VERSION ""

NS_ :

BS_:

BU_: ACCM BMS CHM DCDC GWM HVAC IPK SRS TEM

BO_ 80 BMSChargerCmd: 8 BMS
 SG_ HVCurrentCmd : 7|16@0+  (0.1,0) [0|6553.5] "A"  Vector__XXX
 SG_ MaxVoltage   : 23|16@0+ (0.1,0) [0|6553.5] "V"  Vector__XXX

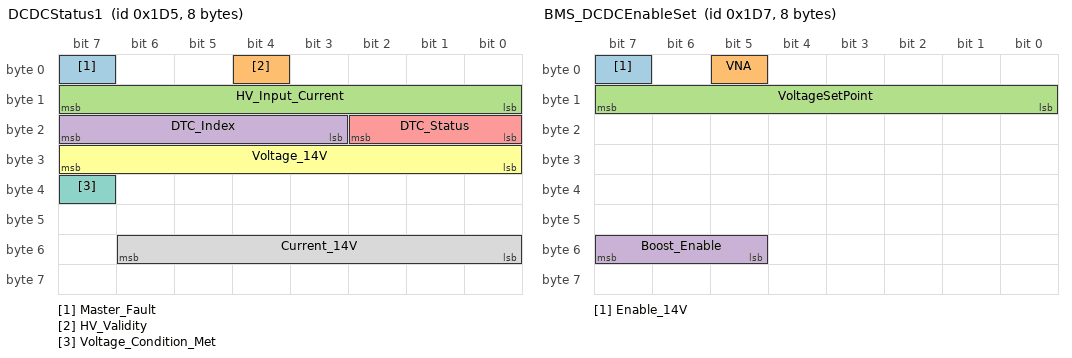
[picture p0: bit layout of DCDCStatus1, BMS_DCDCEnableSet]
BO_ 469 DCDCStatus1: 8 DCDC
 SG_ Master_Fault : 7|1@0+ (1,0) [0|1] "" Vector__XXX
 SG_ HV_Validity : 4|1@0+ (1,0) [0|1] "" Vector__XXX
 SG_ HV_Input_Current : 15|8@0+ (0.1,0) [0|25.5] "A" Vector__XXX
 SG_ DTC_Index : 23|5@0+ (1,0) [0|31] "" Vector__XXX
 SG_ DTC_Status : 18|3@0+ (1,0) [0|7] "" Vector__XXX
 SG_ Voltage_14V : 31|8@0+ (0.078431,0) [0|20] "V" Vector__XXX
 SG_ Voltage_Condition_Met : 39|1@0+ (1,0) [0|1] "" Vector__XXX
 SG_ Current_14V : 54|7@0+ (2,0) [0|254] "A" Vector__XXX

BO_ 471 BMS_DCDCEnableSet: 8 BMS
 SG_ Enable_14V : 7|1@0+ (1,0) [0|1] "" DCDC
 SG_ VNA : 5|1@0+ (1,0) [0|1] "" DCDC
 SG_ VoltageSetPoint : 15|8@0+ (0.022,10.437) [10.437|16.047] "V" DCDC
 SG_ Boost_Enable : 55|3@0+ (1,0) [0|7] "" DCDC

BO_ 624 BMS_FaultStatus: 8 BMS
 SG_ BMSFaultSeverity : 7|4@0+ (1,0) [0|6] "" GWM
 SG_ BMSFaultCode : 3|4@0+ (1,0) [0|15] "" GWM

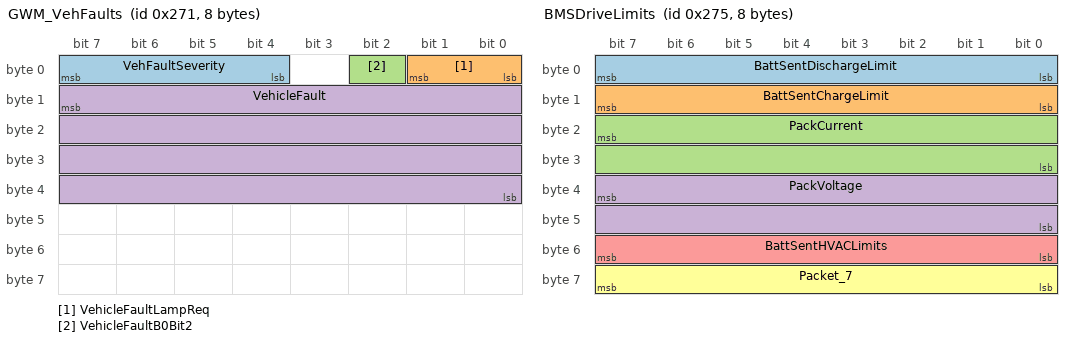
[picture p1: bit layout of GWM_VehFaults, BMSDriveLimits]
BO_ 625 GWM_VehFaults: 8 GWM
 SG_ VehFaultSeverity : 7|4@0+ (1,0) [0|15] "" IPK
 SG_ VehicleFaultLampReq : 1|2@0+ (1,0) [0|3] "" IPK
 SG_ VehicleFaultB0Bit2 : 2|1@0+ (1,0) [0|1] "" Vector__XXX
 SG_ VehicleFault : 15|32@0+ (1,0) [0|4294967295] "" Vector__XXX

BO_ 628 ChrgrSysFaultsTemp: 8 CHM

BO_ 629 BMSDriveLimits: 8 BMS
 SG_ BattSentDischargeLimit : 7|8@0+   (2,0)         [0|510]          "A"  Vector__XXX
 SG_ BattSentChargeLimit    : 15|8@0+  (2,0)         [0|510]          "A"  Vector__XXX
 SG_ PackCurrent            : 23|16@0+ (0.1,-3276.8) [-3276.8|3276.7] "A"  Vector__XXX
 SG_ PackVoltage            : 39|16@0+ (1,0)         [0|65535]        "V"  Vector__XXX
 SG_ BattSentHVACLimits     : 55|8@0+  (2,0)         [0|510]          "A"  Vector__XXX
 SG_ Packet_7               : 63|8@0+  (1,0)         [0|255]          ""   Vector__XXX

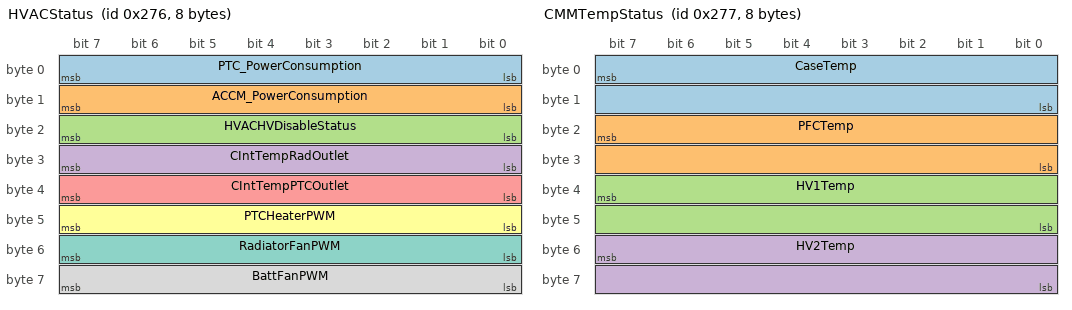
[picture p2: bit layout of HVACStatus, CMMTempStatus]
BO_ 630 HVACStatus: 8 HVAC
 SG_ PTC_PowerConsumption  : 7|8@0+  (0.1,0)      [0|25.5]   "kW"   Vector__XXX
 SG_ ACCM_PowerConsumption : 15|8@0+ (0.1,0)      [0|25.5]   "kW"   Vector__XXX
 SG_ HVACHVDisableStatus   : 23|8@0+ (1,0)        [0|255]    ""     Vector__XXX
 SG_ CIntTempRadOutlet     : 31|8@0+ (1,-40)      [-40|215]  "degC" Vector__XXX
 SG_ CIntTempPTCOutlet     : 39|8@0+ (1,-40)      [-40|215]  "degC" Vector__XXX
 SG_ PTCHeaterPWM          : 47|8@0+ (0.392157,0) [0|100]    "%"    Vector__XXX
 SG_ RadiatorFanPWM        : 55|8@0+ (0.392157,0) [0|100]    "%"    Vector__XXX
 SG_ BattFanPWM            : 63|8@0+ (0.392157,0) [0|100]    "%"    Vector__XXX

BO_ 631 CMMTempStatus: 8 CHM
 SG_ CaseTemp : 7|16@0+ (0.03125,0) [0|2047] "degC" Vector__XXX
 SG_ PFCTemp : 23|16@0+ (0.03125,0) [0|2047] "degC" Vector__XXX
 SG_ HV1Temp : 39|16@0+ (0.03125,0) [0|2047] "degC" Vector__XXX
 SG_ HV2Temp : 55|16@0+ (0.03125,0) [0|2047] "degC" Vector__XXX

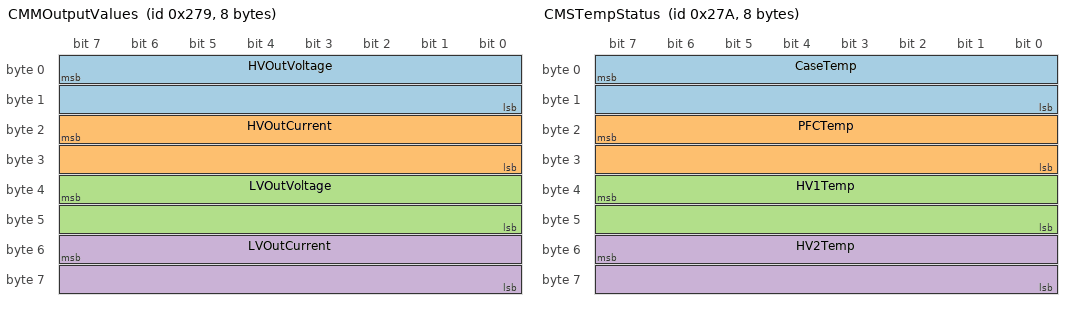
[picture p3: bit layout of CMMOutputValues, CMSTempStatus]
BO_ 633 CMMOutputValues: 8 CHM
 SG_ HVOutVoltage : 7|16@0+ (0.03125,0) [0|2047] "V" Vector__XXX
 SG_ HVOutCurrent : 23|16@0+ (0.03125,0) [0|2047] "A" Vector__XXX
 SG_ LVOutVoltage : 39|16@0+ (0.03125,0) [0|2047] "V" Vector__XXX
 SG_ LVOutCurrent : 55|16@0+ (0.03125,0) [0|2047] "A" Vector__XXX

BO_ 634 CMSTempStatus: 8 CHM
 SG_ CaseTemp : 7|16@0+ (0.03125,0) [0|2047] "degC" Vector__XXX
 SG_ PFCTemp : 23|16@0+ (0.03125,0) [0|2047] "degC" Vector__XXX
 SG_ HV1Temp : 39|16@0+ (0.03125,0) [0|2047] "degC" Vector__XXX
 SG_ HV2Temp : 55|16@0+ (0.03125,0) [0|2047] "degC" Vector__XXX

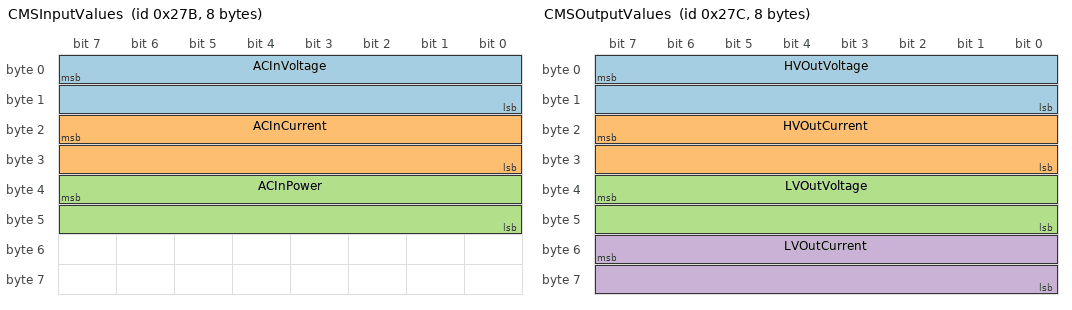
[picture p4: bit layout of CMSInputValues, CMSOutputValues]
BO_ 635 CMSInputValues: 8 CHM
 SG_ ACInVoltage : 7|16@0+ (0.03125,0) [0|2047] "V" Vector__XXX
 SG_ ACInCurrent : 23|16@0+ (0.03125,0) [0|2047] "A" Vector__XXX
 SG_ ACInPower : 39|16@0+ (0.03125,0) [0|2047] "W" Vector__XXX

BO_ 636 CMSOutputValues: 8 CHM
 SG_ HVOutVoltage : 7|16@0+ (0.03125,0) [0|2047] "V" Vector__XXX
 SG_ HVOutCurrent : 23|16@0+ (0.03125,0) [0|2047] "A" Vector__XXX
 SG_ LVOutVoltage : 39|16@0+ (0.03125,0) [0|2047] "V" Vector__XXX
 SG_ LVOutCurrent : 55|16@0+ (0.03125,0) [0|2047] "A" Vector__XXX

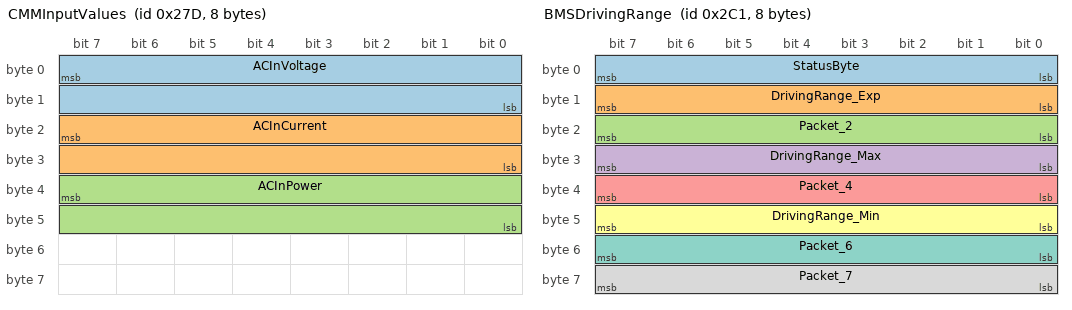
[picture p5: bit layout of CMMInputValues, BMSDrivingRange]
BO_ 637 CMMInputValues: 8 CHM
 SG_ ACInVoltage : 7|16@0+ (0.03125,0) [0|2047] "V" Vector__XXX
 SG_ ACInCurrent : 23|16@0+ (0.03125,0) [0|2047] "A" Vector__XXX
 SG_ ACInPower : 39|16@0+ (0.03125,0) [0|2047] "W" Vector__XXX

BO_ 705 BMSDrivingRange: 8 BMS
 SG_ StatusByte       : 7|8@0+  (1,0)         [0|255]      ""  Vector__XXX
 SG_ DrivingRange_Exp : 15|8@0+ (1.17,-17.85) [-17.85|280] "mi" Vector__XXX
 SG_ Packet_2         : 23|8@0+ (1,0)         [0|255]      ""  Vector__XXX
 SG_ DrivingRange_Max : 31|8@0+ (1.14,-21.0)  [-21|269]    "mi" Vector__XXX
 SG_ Packet_4         : 39|8@0+ (1,0)         [0|255]      ""  Vector__XXX
 SG_ DrivingRange_Min : 47|8@0+ (1.0,-21.58)  [-21.58|234] "mi" Vector__XXX
 SG_ Packet_6         : 55|8@0+ (1,0)         [0|255]      ""  Vector__XXX
 SG_ Packet_7         : 63|8@0+ (1,0)         [0|255]      ""  Vector__XXX

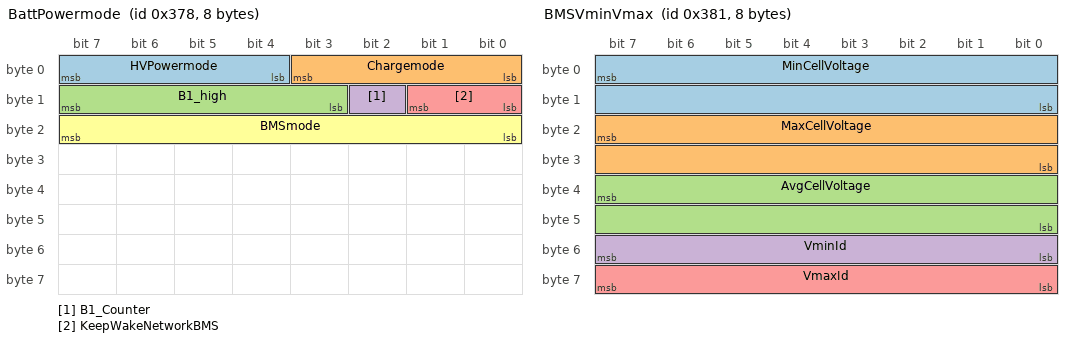
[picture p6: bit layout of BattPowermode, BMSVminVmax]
BO_ 888 BattPowermode: 8 BMS
 SG_ HVPowermode        : 7|4@0+  (1,0) [0|15]  ""  Vector__XXX
 SG_ Chargemode         : 3|4@0+  (1,0) [0|15]  ""  Vector__XXX
 SG_ B1_high            : 15|5@0+ (1,0) [0|31]  ""  Vector__XXX
 SG_ B1_Counter         : 10|1@0+ (1,0) [0|1]   ""  Vector__XXX
 SG_ KeepWakeNetworkBMS : 9|2@0+  (1,0) [0|3]   ""  Vector__XXX
 SG_ BMSmode            : 23|8@0+ (1,0) [0|255] ""  Vector__XXX

BO_ 897 BMSVminVmax: 8 BMS
 SG_ MinCellVoltage : 7|16@0+ (1,0) [2500|3650] "mV" Vector__XXX
 SG_ MaxCellVoltage : 23|16@0+ (1,0) [2500|3650] "mV" Vector__XXX
 SG_ AvgCellVoltage : 39|16@0+ (1,0) [2500|3650] "mV" Vector__XXX
 SG_ VminId : 55|8@0+ (1,0) [0|255] "" Vector__XXX
 SG_ VmaxId : 63|8@0+ (1,0) [0|255] "" Vector__XXX

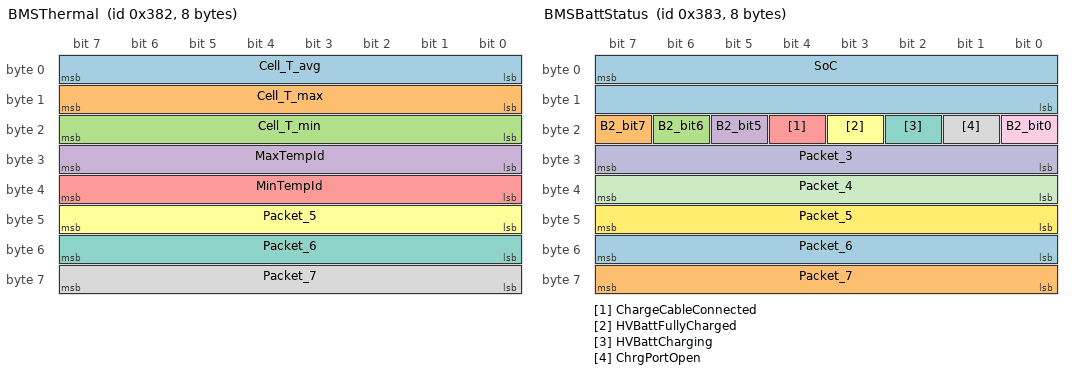
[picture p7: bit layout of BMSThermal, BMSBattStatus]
BO_ 898 BMSThermal: 8 BMS
 SG_ Cell_T_avg : 7|8@0+  (1,-128) [-128|127] "degC" Vector__XXX
 SG_ Cell_T_max : 15|8@0+ (1,-128) [-128|127] "degC" Vector__XXX
 SG_ Cell_T_min : 23|8@0+ (1,-128) [-128|127] "degC" Vector__XXX
 SG_ MaxTempId  : 31|8@0+ (1,0)    [0|255]    ""     Vector__XXX
 SG_ MinTempId  : 39|8@0+ (1,0)    [0|255]    ""     Vector__XXX
 SG_ Packet_5   : 47|8@0+ (1,0)    [0|255]    ""     Vector__XXX
 SG_ Packet_6   : 55|8@0+ (1,0)    [0|255]    ""     Vector__XXX
 SG_ Packet_7   : 63|8@0+ (1,0)    [0|255]    ""     Vector__XXX

BO_ 899 BMSBattStatus: 8 BMS
 SG_ SoC                  : 7|16@0+  (0.1,0) [0|100]  "%"  Vector__XXX
 SG_ B2_bit7              : 23|1@0+  (1,0)   [0|1]     ""   Vector__XXX
 SG_ B2_bit6              : 22|1@0+  (1,0)   [0|1]     ""   Vector__XXX
 SG_ B2_bit5              : 21|1@0+  (1,0)   [0|1]     ""   Vector__XXX
 SG_ ChargeCableConnected : 20|1@0+  (1,0)   [0|1]     ""   Vector__XXX
 SG_ HVBattFullyCharged   : 19|1@0+  (1,0)   [0|1]     ""   Vector__XXX
 SG_ HVBattCharging       : 18|1@0+  (1,0)   [0|1]     ""   Vector__XXX
 SG_ ChrgPortOpen         : 17|1@0+  (1,0)   [0|1]     ""   Vector__XXX
 SG_ B2_bit0              : 16|1@0+  (1,0)   [0|1]     ""   Vector__XXX
 SG_ Packet_3             : 31|8@0+  (1,0)   [0|255]   ""   Vector__XXX
 SG_ Packet_4             : 39|8@0+  (1,0)   [0|255]   ""   Vector__XXX
 SG_ Packet_5             : 47|8@0+  (1,0)   [0|255]   ""   Vector__XXX
 SG_ Packet_6             : 55|8@0+  (1,0)   [0|255]   ""   Vector__XXX
 SG_ Packet_7             : 63|8@0+  (1,0)   [0|255]   ""   Vector__XXX

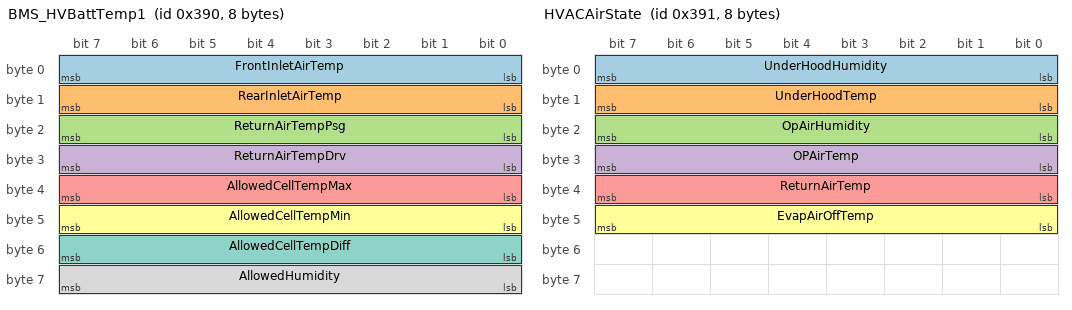
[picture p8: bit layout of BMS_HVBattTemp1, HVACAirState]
BO_ 912 BMS_HVBattTemp1: 8 BMS
 SG_ FrontInletAirTemp   : 7|8@0+  (1,-128) [-128|127] "degC" Vector__XXX
 SG_ RearInletAirTemp    : 15|8@0+ (1,-128) [-128|127] "degC" Vector__XXX
 SG_ ReturnAirTempPsg    : 23|8@0+ (1,-128) [-128|127] "degC" Vector__XXX
 SG_ ReturnAirTempDrv    : 31|8@0+ (1,-128) [-128|127] "degC" Vector__XXX
 SG_ AllowedCellTempMax  : 39|8@0+ (1,-128) [-128|127] "degC" Vector__XXX
 SG_ AllowedCellTempMin  : 47|8@0+ (1,-128) [-128|127] "degC" Vector__XXX
 SG_ AllowedCellTempDiff : 55|8@0+ (1,0)    [0|255]    "degC" Vector__XXX
 SG_ AllowedHumidity     : 63|8@0+ (1,0)    [0|255]    "%"    Vector__XXX

BO_ 913 HVACAirState: 8 HVAC
 SG_ UnderHoodHumidity : 7|8@0+  (2.0,0)  [0|100]    "%"    Vector__XXX
 SG_ UnderHoodTemp     : 15|8@0+ (1,-128) [-128|127]  "degC" Vector__XXX
 SG_ OpAirHumidity     : 23|8@0+ (2.0,0)  [0|100]    "%"    Vector__XXX
 SG_ OPAirTemp         : 31|8@0+ (1,-128) [-128|127]  "degC" Vector__XXX
 SG_ ReturnAirTemp     : 39|8@0+ (1,-128) [-128|127]  "degC" Vector__XXX
 SG_ EvapAirOffTemp    : 47|8@0+ (1,-128) [-128|127]  "degC" Vector__XXX

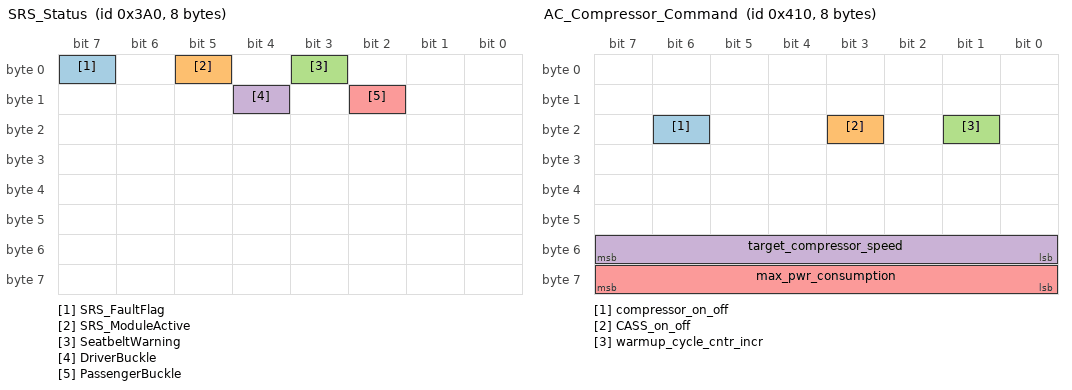
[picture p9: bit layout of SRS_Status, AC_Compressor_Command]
BO_ 928 SRS_Status: 8 SRS
 SG_ SRS_FaultFlag    : 7|1@0+ (1,0) [0|1] "" Vector__XXX
 SG_ SRS_ModuleActive : 5|1@0+ (1,0) [0|1] "" Vector__XXX
 SG_ SeatbeltWarning  : 3|1@0+ (1,0) [0|1] "" Vector__XXX
 SG_ DriverBuckle     : 12|1@0+ (1,0) [0|1] "" Vector__XXX
 SG_ PassengerBuckle  : 10|1@0+ (1,0) [0|1] "" Vector__XXX

BO_ 1040 AC_Compressor_Command: 8 HVAC
 SG_ compressor_on_off       : 22|1@0+ (1,0)   [0|1]     ""    ACCM
 SG_ CASS_on_off             : 19|1@0+ (1,0)   [0|1]     ""    ACCM
 SG_ warmup_cycle_cntr_incr  : 17|1@0+ (1,0)   [0|1]     ""    ACCM
 SG_ target_compressor_speed : 55|8@0+ (60,0)  [0|15180] "rpm" ACCM
 SG_ max_pwr_consumption     : 63|8@0+ (0.1,0) [0|25.3]  "kW"  ACCM

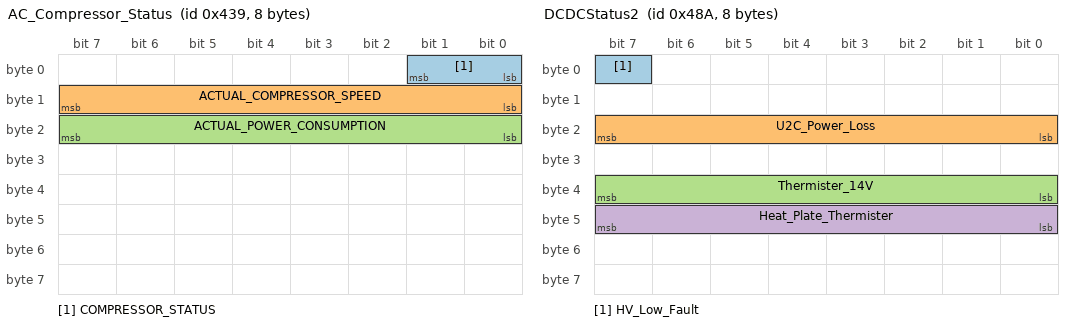
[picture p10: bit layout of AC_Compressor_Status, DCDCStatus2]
BO_ 1081 AC_Compressor_Status: 8 ACCM
 SG_ COMPRESSOR_STATUS : 1|2@0+ (1,0) [0|3] "" Vector__XXX
 SG_ ACTUAL_COMPRESSOR_SPEED : 15|8@0+ (60,0) [0|15180] "rpm" Vector__XXX
 SG_ ACTUAL_POWER_CONSUMPTION : 23|8@0+ (0.1,0) [0|25.3] "kW" Vector__XXX

BO_ 1162 DCDCStatus2: 8 DCDC
 SG_ HV_Low_Fault : 7|1@0+ (1,0) [0|1] "" Vector__XXX
 SG_ U2C_Power_Loss : 23|8@0+ (2,0) [0|510] "W" Vector__XXX
 SG_ Thermister_14V : 39|8@0+ (1,-40) [-40|215] "degC" Vector__XXX
 SG_ Heat_Plate_Thermister : 47|8@0+ (1,-40) [-40|215] "degC" Vector__XXX

BO_ 1169 IPK_Status: 8 IPK
 SG_ IPK_FaultLamps : 2|3@0+ (1,0) [0|7] "" Vector__XXX

BO_ 1170 IPK_Echo: 8 Vector__XXX

BO_ 1557 ChrgrSysLimits: 8 CHM

BO_ 1558 ChrgrSysCtrlEcho: 8 CHM

BO_ 1559 ChrgrSysSts: 8 CHM
 SG_ ChrgrSysBusVoltage : 7|16@0+ (0.1,0) [0|6553.5] "V" Vector__XXX
 SG_ ChrgrSysBusCurrent : 31|8@0+ (0.1,0) [0|25.5]   "A" Vector__XXX

BO_ 1568 BMS_Recvd_0x620: 8 Vector__XXX

BO_ 1786 GWM_VIN: 8 GWM
 SG_ VIN_Frame M  : 7|8@0+  (1,0) [0|2]    "" Vector__XXX
 SG_ VIN_C01  m0  : 15|8@0+ (1,0) [32|127] "" Vector__XXX
 SG_ VIN_C02  m0  : 23|8@0+ (1,0) [32|127] "" Vector__XXX
 SG_ VIN_C03  m0  : 31|8@0+ (1,0) [32|127] "" Vector__XXX
 SG_ VIN_C04  m0  : 39|8@0+ (1,0) [32|127] "" Vector__XXX
 SG_ VIN_C05  m0  : 47|8@0+ (1,0) [32|127] "" Vector__XXX
 SG_ VIN_C06  m0  : 55|8@0+ (1,0) [32|127] "" Vector__XXX
 SG_ VIN_C07  m0  : 63|8@0+ (1,0) [32|127] "" Vector__XXX
 SG_ VIN_C08  m1  : 15|8@0+ (1,0) [32|127] "" Vector__XXX
 SG_ VIN_C09  m1  : 23|8@0+ (1,0) [32|127] "" Vector__XXX
 SG_ VIN_C10  m1  : 31|8@0+ (1,0) [32|127] "" Vector__XXX
 SG_ VIN_C11  m1  : 39|8@0+ (1,0) [32|127] "" Vector__XXX
 SG_ VIN_C12  m1  : 47|8@0+ (1,0) [32|127] "" Vector__XXX
 SG_ VIN_C13  m1  : 55|8@0+ (1,0) [32|127] "" Vector__XXX
 SG_ VIN_C14  m1  : 63|8@0+ (1,0) [32|127] "" Vector__XXX
 SG_ VIN_C15  m2  : 15|8@0+ (1,0) [32|127] "" Vector__XXX
 SG_ VIN_C16  m2  : 23|8@0+ (1,0) [32|127] "" Vector__XXX
 SG_ VIN_C17  m2  : 31|8@0+ (1,0) [32|127] "" Vector__XXX

BO_ 1834 BMS_Recvd_0x72A: 1 Vector__XXX

CM_ BO_ 80 "BMS charger command. B4-B5=suspected rolling counter/validation (charger throttles to ~6A when non-baseline; frame likely rejected). B6-B7=unknown. BMS Charger Sys Main Current not cleanly decoded -- may be measured (not commanded) or in B6-B7.";
CM_ BO_ 469 "HV-to-14V converter status. Source: DCDC hardware manual.";
CM_ BO_ 471 "BMS command to DCDC converter. Source: DCDC hardware manual.";
CM_ BO_ 624 "BMS fault status. B0 high nibble=BMSFaultSeverity (0=No Fault, 1-6 progressively severe), low nibble=BMSFaultCode. VICD: BMS_Recvd 0x270, handler 0x15EF. B6/B7 active but unknown.";
CM_ BO_ 625 "GWM VehFaults relay on B CAN (1 frame after 0x270 BMS source). B0=fault severity + lamp request + test flag. B1-B4=VehicleFault (32-bit fault code).";
CM_ SG_ 625 VehFaultSeverity "Encoding 0-6 same as 0x270 BMSFaultSeverity.";
CM_ SG_ 625 VehicleFaultLampReq "0=OFF, 1=YELLOW, 2=RED, 3=INVALID.";
CM_ SG_ 625 VehicleFaultB0Bit2 "Set during key-on lamp test and briefly at drive end. NOT set during active faults -- lamp-test-active flag.";
CM_ BO_ 628 "LabVIEW: ChrgrSysFaultsTemp (CMM_glb.xml). Signals: ChrgrFaults_0..5 (uint16+uint8) + Chrgr1Temp, Chrgr2Temp (uint8). Byte-level encoding unconfirmed -- LabVIEW cluster exceeds 8 bytes when packed sequentially.";
CM_ BO_ 629 "BMS battery power limits and measurements. B0=BattSentDischargeLimit/MotorDriveLimit (CODACAN alias, same byte). B1=BattSentChargeLimit. B2-B3=PackCurrent. B4-B5=PackVoltage. B6=BattSentHVACLimits. B7=unidentified, possibly 4th current limit. Note: B4 always=1 in normal LFP operation (pack voltage 312-380V keeps uint16 MSB=1) -- prior 'HVActive' label was a misidentification.";
CM_ SG_ 629 BattSentDischargeLimit "CODACAN alias: MotorDriveLimit.";
CM_ SG_ 629 PackCurrent "Positive = charging.";
CM_ SG_ 629 PackVoltage "B4=0 is a sentinel (triggers ~4V display); normal LFP operation keeps B4=1.";
CM_ BO_ 630 "HVAC power/thermal status. 10 Hz. Sender: HVAC ECU. B0=PTC power, B1=ACCM power, B2=HV disable status (sub-byte layout unresolved), B3=coolant outlet temp, B4=PTC outlet temp, B5=PTC heater PWM, B6=radiator fan PWM, B7=batt cooling fan PWM. PWM signals use open-drain hardware; CODACAN 'Inverted' label = wire polarity only, not CAN encoding.";
CM_ SG_ 630 HVACHVDisableStatus "PROVISIONAL encoding: 0=Invalid, 2=enum-3 (no label), 5=All HV Components disabled, 8=All HV Components not disabled. Sub-byte bit layout unresolved.";
CM_ BO_ 631 "CMM (master charger module) temperatures.";
CM_ BO_ 633 "CMM charger output measurements. HVOutVoltage matches pack voltage from C CAN.";
CM_ BO_ 634 "CMS (slave charger module) temperatures. Same Lear OBC hardware as CMM.";
CM_ BO_ 635 "CMS charger input measurements. Same Lear OBC hardware as CMM.";
CM_ BO_ 636 "CMS charger output measurements. CMS is the slave charger module; CMM is master.";
CM_ BO_ 637 "CMM (master charger module) input measurements.";
CM_ BO_ 705 "BMS driving range estimates. B0=StatusByte (flips all readings at raw=0x70, likely health/CRC). B1=DrivingRange_Exp, B3=DrivingRange_Max, B5=DrivingRange_Min. B2/B4/B6=0x00 padding. All range signals provisional -- scales ~1.1-1.17, units likely miles.";
CM_ SG_ 705 DrivingRange_Exp "PROVISIONAL: scale unconfirmed, units likely miles.";
CM_ SG_ 705 DrivingRange_Max "PROVISIONAL: scale unconfirmed, units likely miles.";
CM_ SG_ 705 DrivingRange_Min "PROVISIONAL: scale unconfirmed, units likely miles.";
CM_ BO_ 888 "BMS mode and network management. B0[7:4]=HVPowermode, B0[3:0]=Chargemode, B1[1:0]=KeepWakeNetworkBMS, B1[2]=rolling counter, B1[7:3]=always 0, B2=BMSmode. B3-B7 unused.";
CM_ SG_ 888 HVPowermode "0=Invalid, 2=HV Off Imminent, 3=HV On Drive (provisional), 4=HV On Drive, 5=HV On Charge, 6=HV On Support (provisional), 7=HV On Support (provisional). Values 8-F show as raw numerics in CODACAN.";
CM_ SG_ 888 Chargemode "0=Invalid, 1=No Prox, 2=Prox Present (open/wait), 3=Charging, 4=Charge Complete (provisional), 5=Maintenance Charging (provisional), 6=Invalid, 15=Invalid.";
CM_ SG_ 888 KeepWakeNetworkBMS "Bit0=0 -> Network Alive Request, bit0=1 -> No Network Request. Bit1 is don't-care.";
CM_ SG_ 888 B1_Counter "1-bit rolling counter, toggles every frame at ~6Hz.";
CM_ SG_ 888 B1_high "B1[7:3] 5-bit field. Always 0 in available captures. Purpose unknown (possible counter or reserved).";
CM_ BO_ 897 "BMS cell voltage extremes. B0-B1=min, B2-B3=max, B4-B5=avg. OV cutoff at 3750 mV. B6=VminId, B7=VmaxId (cell indices).";
CM_ SG_ 897 MinCellVoltage "104-cell LFP pack.";
CM_ SG_ 897 MaxCellVoltage "OV cutoff at 3750 mV.";
CM_ SG_ 897 VminId "0-based index.";
CM_ SG_ 897 VmaxId "0-based index.";
CM_ BO_ 898 "BMS cell temperature stats. B0=Cell_T_avg, B1=Cell_T_max (provisional), B2=Cell_T_min (provisional), B3=MaxTempId, B4=MinTempId.";
CM_ SG_ 898 Cell_T_avg "Invalid sentinels: 0x00 (standby), 0x33 (charge stopped).";
CM_ SG_ 898 Cell_T_max "PROVISIONAL.";
CM_ SG_ 898 Cell_T_min "PROVISIONAL.";
CM_ BO_ 899 "BMS battery status. B0-B1=SoC. B2=packed boolean flags (see signals). B3-B7 unknown. PROVISIONAL: B2 bit2/bit1 (HVBattCharging/ChrgPortOpen) assignment may be swapped.";
CM_ SG_ 899 HVBattCharging "PROVISIONAL: may swap identity with ChrgPortOpen (B2 bit1).";
CM_ SG_ 899 ChrgPortOpen "PROVISIONAL: may swap identity with HVBattCharging (B2 bit2). Toggles rapidly at session start (~0.3s period), consistent with J1772 handshake.";
CM_ SG_ 899 B2_bit7 "Always 0 in available data. Possibly LowSOC, HVBattOverheat, or HVBattMalfunc.";
CM_ SG_ 899 B2_bit0 "Always 0 in available data. Possibly J772Activity (J1772 pilot signal active).";
CM_ BO_ 912 "BMS HV battery temperature zone sensors. B0=FrontInletAirTemp, B1=RearInletAirTemp, B2=ReturnAirTempPsg, B3=ReturnAirTempDrv, B4=AllowedCellTempMax, B5=AllowedCellTempMin, B6=AllowedCellTempDiff (non-negative delta, no offset), B7=AllowedHumidity (scale TBD). Sender: BMS.";
CM_ SG_ 912 AllowedCellTempDiff "Non-negative temperature delta (no offset, unlike other temp signals).";
CM_ SG_ 912 AllowedHumidity "PROVISIONAL: scale TBD.";
CM_ BO_ 913 "HVAC ambient air state. B0=UnderHoodHumidity, B1=UnderHoodTemp, B2=OpAirHumidity, B3=OPAirTemp, B4=ReturnAirTemp, B5=EvapAirOffTemp (not in original CODACAN field list). B6-B7 inactive. Sender: HVAC ECU. Humidity signals may be marked Inverted in CODACAN -- verify direction against real data.";
CM_ SG_ 913 OPAirTemp "Outside/ambient air temperature.";
CM_ BO_ 1040 "AC compressor command. Ford AM64-19D623-AB electric scroll compressor. B0=raw command byte (boolean signals observed but bit assignments unresolved).";
CM_ SG_ 1040 compressor_on_off "~360ms latency before status reports Running.";
CM_ SG_ 1040 target_compressor_speed "Hardware max 6000 rpm.";
CM_ SG_ 1040 max_pwr_consumption "Hardware max 4.5 kW.";
CM_ BO_ 1081 "AC compressor status feedback. 10 Hz.";
CM_ SG_ 1081 COMPRESSOR_STATUS "0=Standby (HV available, no run cmd), 1=Running, 2=CASS Complete (self-test/startup sequence complete), 3=Off (no HV or shutdown).";
CM_ BO_ 1162 "DCDC secondary status with temperatures. Source: DCDC hardware manual.";
CM_ BO_ 1557 "LabVIEW: ChrgrSysLimits (CMM_glb.xml). Float signals likely use div32 encoding -- shown as 8-bit placeholder, scale tentative.";
CM_ BO_ 1558 "LabVIEW: ChrgrSysCtrlEcho (CMM_glb.xml). Echo of charger control commands. Encoding tentative.";
CM_ BO_ 1559 "Charger system bus measurements. B2=unknown (always 0x00; may be MSB of ChrgrSysBusCurrent uint16). B4=status flags (0x83/0x84, bit0 toggles). B5=0x00. B6=bimodal 0x00/0x1F transient. B7=0x00. LabVIEW names B4-5=ChrgrSys12VSysVoltage, B6-7=ChrgrSys12VSysCurrent but observed values do not match div32.";
CM_ BO_ 1568 "VICD: BMS_Recvd 0x620. Sparse decode, cluster unknown.";
CM_ BO_ 1834 "VICD: BMS_Recvd 0x72A. Simple byte copy, cluster unknown.";
CM_ BO_ 928 "SRS airbag module + seatbelt switch status. B CAN only, 10 Hz. B0: SRS status bits + seatbelt warning. B1: buckle switches.";
CM_ SG_ 928 SRS_ModuleActive "Set in both normal and fault conditions.";
CM_ SG_ 928 SRS_FaultFlag "Active when SRS DTC present (e.g. B1382/B2505 in parts car).";
CM_ SG_ 928 SeatbeltWarning "B0.bit3. 1=warning active. Cleared when driver buckles. Medium confidence -- needs test with occupied passenger seat to confirm combined vs driver-only semantics.";
CM_ SG_ 928 DriverBuckle "B1.bit4. 1=unbuckled, 0=buckled. HIGH confidence.";
CM_ SG_ 928 PassengerBuckle "B1.bit2. 1=unbuckled, 0=buckled. HIGH confidence. Test used unoccupied passenger seat -- driver reached over to buckle it.";
CM_ BO_ 1169 "IPK instrument cluster fault lamp status on B CAN. B0 is a key-on latch -- set once at key-on, does NOT change during lamp test or mid-drive faults. B0 bits 2-0=fault lamp indicators. B0 bit 3=IPK_B0_Active. B1 bits 4,3,1 set in normal but cleared with active faults -- encoding unknown.";
CM_ SG_ 1169 IPK_FaultLamps "Which bit maps to which module (ABS/SRS/HVAC) is unresolved.";
CM_ BO_ 1170 "UNKNOWN: 0x492. All zeros in parts car dataset. Possible IPK echo or secondary status frame.";
CM_ BO_ 1786 "GWM broadcasts VIN on B CAN at 10 Hz as a 3-frame sequence. B0=VIN_FrameCounter (0/1/2); B1-B7=7 ASCII chars per frame. Frame 0: chars 1-7; Frame 1: chars 8-14; Frame 2: chars 15-17 + padding. Same ID rebroadcast on D CAN.";
CM_ SG_ 1786 VIN_Frame "Each byte B1-B7 is one raw ASCII character of the VIN.";

VAL_ 888 HVPowermode 0 "Invalid" 2 "HV Off Imminent" 3 "HV On Drive" 4 "HV On Drive" 5 "HV On Charge" 6 "HV On Support" 7 "HV On Support" ;
VAL_ 888 Chargemode 0 "Invalid" 1 "No Prox" 2 "Prox Present Open Wait Active" 3 "Charging" 4 "Charge Complete" 5 "Maintenance Charging" 6 "Invalid" 15 "Invalid" ;
VAL_ 888 KeepWakeNetworkBMS 0 "Network Alive Request" 1 "No Network Request" 2 "Network Alive Request" 3 "No Network Request" ;
VAL_ 1081 COMPRESSOR_STATUS 0 "Standby" 1 "Running" 2 "CASS Complete" 3 "Off" ;
VAL_ 624 BMSFaultSeverity 0 "No Fault" 1 "Information Only, No Limiting" 2 "Minor Performance Limiting" 3 "Limited Performance" 4 "Heavily Limited Performance, Contactors Will Not Close" 5 "Heavily Limited Performance, Operation Should Be Stopped" 6 "ALL HV Components Should Be Disabled, BMS Will Open" 7 "Reserved" 8 "Reserved" 9 "Reserved" 10 "Reserved" 11 "Reserved" 12 "Reserved" 13 "Reserved" 14 "Reserved" 15 "Reserved" ;
